AUTOSAR XML (schema 00048)
package /MICROSAR/NvM_swc/DataTypes
  impl type NvM_RequestResultType: compu {0=NVM_REQ_OK, 1=NVM_REQ_NOT_OK, 2=NVM_REQ_PENDING, 3=NVM_REQ_INTEGRITY_FAILED, 4=NVM_REQ_BLOCK_SKIPPED, 5=NVM_REQ_NV_INVALIDATED, 6=NVM_REQ_CANCELED, 7=NVM_REQ_REDUNDANCY_FAILED, 8=NVM_REQ_RESTORED_FROM_ROM}, range raw 0..8, implementation-data-type=uint8
  impl type NvM_BlockIdType: range raw 1..32767, implementation-data-type=uint16
package /MICROSAR/NvM_swc/Interfaces
  client server interface NvMAdministration: is-service=true, service-kind=NON-VOLATILE-RAM-MANAGER
    operation SetBlockProtection: possible-error=NvMAdministration/E_NOT_OK
      arg ProtectionEnabled: type=boolean, direction=IN
    error E_NOT_OK: error-code=1
  client server interface NvMService_AC3_SRBS_Defs: is-service=true, service-kind=NON-VOLATILE-RAM-MANAGER
    7 x operation, all with possible-error=NvMService_AC3_SRBS_Defs/E_NOT_OK:
      GetErrorStatus
        arg ErrorStatus: type=NvM_RequestResultType, direction=OUT
      SetRamBlockStatus
        arg RamBlockStatus: type=boolean, direction=IN
      ReadBlock
        arg DstPtr: type=dtRef_VOID, direction=IN
      WriteBlock
        arg SrcPtr: type=dtRef_const_VOID, direction=IN
      RestoreBlockDefaults
        arg DstPtr: type=dtRef_VOID, direction=IN
      InvalidateNvBlock
      EraseBlock
    error E_NOT_OK: error-code=1
package /MICROSAR/NvM_swc/ComponentTypes
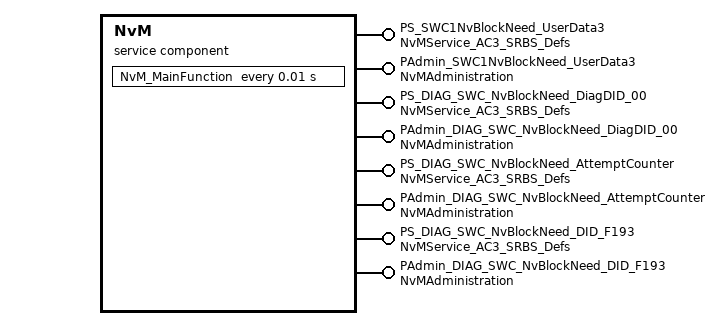
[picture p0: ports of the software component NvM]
  service sw component type NvM: category=SERVICE_COMPONENT
    8 x provide port:
      PS_SWC1NvBlockNeed_UserData3: provided-interface=NvMService_AC3_SRBS_Defs
      PAdmin_SWC1NvBlockNeed_UserData3: provided-interface=NvMAdministration
      PS_DIAG_SWC_NvBlockNeed_DiagDID_00: provided-interface=NvMService_AC3_SRBS_Defs
      PAdmin_DIAG_SWC_NvBlockNeed_DiagDID_00: provided-interface=NvMAdministration
      PS_DIAG_SWC_NvBlockNeed_AttemptCounter: provided-interface=NvMService_AC3_SRBS_Defs
      PAdmin_DIAG_SWC_NvBlockNeed_AttemptCounter: provided-interface=NvMAdministration
      PS_DIAG_SWC_NvBlockNeed_DID_F193: provided-interface=NvMService_AC3_SRBS_Defs
      PAdmin_DIAG_SWC_NvBlockNeed_DID_F193: provided-interface=NvMAdministration
    behavior NvMInternalBehavior: handle-termination-and-restart=NO-SUPPORT
      timing event Timer_NvM_MainFunction: start-on-event=NvM_MainFunction, period=0.01
      32 x operation invoked event:
        OpEventGetErrorStatus_GetErrorStatus_PS_SWC1NvBlockNeed_UserData3: start-on-event=GetErrorStatus, operation=PS_SWC1NvBlockNeed_UserData3.GetErrorStatus
        OpEventSetRamBlockStatus_SetRamBlockStatus_PS_SWC1NvBlockNeed_UserData3: start-on-event=SetRamBlockStatus, operation=PS_SWC1NvBlockNeed_UserData3.SetRamBlockStatus
        OpEventReadBlock_ReadBlock_PS_SWC1NvBlockNeed_UserData3: start-on-event=ReadBlock, operation=PS_SWC1NvBlockNeed_UserData3.ReadBlock
        OpEventWriteBlock_WriteBlock_PS_SWC1NvBlockNeed_UserData3: start-on-event=WriteBlock, operation=PS_SWC1NvBlockNeed_UserData3.WriteBlock
        OpEventRestoreBlockDefaults_RestoreBlockDefaults_PS_SWC1NvBlockNeed_UserData3: start-on-event=RestoreBlockDefaults, operation=PS_SWC1NvBlockNeed_UserData3.RestoreBlockDefaults
        OpEventInvalidateNvBlock_InvalidateNvBlock_PS_SWC1NvBlockNeed_UserData3: start-on-event=InvalidateNvBlock, operation=PS_SWC1NvBlockNeed_UserData3.InvalidateNvBlock
        OpEventEraseBlock_EraseBlock_PS_SWC1NvBlockNeed_UserData3: start-on-event=EraseBlock, operation=PS_SWC1NvBlockNeed_UserData3.EraseBlock
        OpEventSetBlockProtection_SetBlockProtection_PAdmin_SWC1NvBlockNeed_UserData3: start-on-event=SetBlockProtection, operation=PAdmin_SWC1NvBlockNeed_UserData3.SetBlockProtection
        OpEventGetErrorStatus_GetErrorStatus_PS_DIAG_SWC_NvBlockNeed_DiagDID_00: start-on-event=GetErrorStatus, operation=PS_DIAG_SWC_NvBlockNeed_DiagDID_00.GetErrorStatus
        OpEventSetRamBlockStatus_SetRamBlockStatus_PS_DIAG_SWC_NvBlockNeed_DiagDID_00: start-on-event=SetRamBlockStatus, operation=PS_DIAG_SWC_NvBlockNeed_DiagDID_00.SetRamBlockStatus
        OpEventReadBlock_ReadBlock_PS_DIAG_SWC_NvBlockNeed_DiagDID_00: start-on-event=ReadBlock, operation=PS_DIAG_SWC_NvBlockNeed_DiagDID_00.ReadBlock
        OpEventWriteBlock_WriteBlock_PS_DIAG_SWC_NvBlockNeed_DiagDID_00: start-on-event=WriteBlock, operation=PS_DIAG_SWC_NvBlockNeed_DiagDID_00.WriteBlock
        OpEventRestoreBlockDefaults_RestoreBlockDefaults_PS_DIAG_SWC_NvBlockNeed_DiagDID_00: start-on-event=RestoreBlockDefaults, operation=PS_DIAG_SWC_NvBlockNeed_DiagDID_00.RestoreBlockDefaults
        OpEventInvalidateNvBlock_InvalidateNvBlock_PS_DIAG_SWC_NvBlockNeed_DiagDID_00: start-on-event=InvalidateNvBlock, operation=PS_DIAG_SWC_NvBlockNeed_DiagDID_00.InvalidateNvBlock
        OpEventEraseBlock_EraseBlock_PS_DIAG_SWC_NvBlockNeed_DiagDID_00: start-on-event=EraseBlock, operation=PS_DIAG_SWC_NvBlockNeed_DiagDID_00.EraseBlock
        OpEventSetBlockProtection_SetBlockProtection_PAdmin_DIAG_SWC_NvBlockNeed_DiagDID_00: start-on-event=SetBlockProtection, operation=PAdmin_DIAG_SWC_NvBlockNeed_DiagDID_00.SetBlockProtection
        OpEventGetErrorStatus_GetErrorStatus_PS_DIAG_SWC_NvBlockNeed_AttemptCounter: start-on-event=GetErrorStatus, operation=PS_DIAG_SWC_NvBlockNeed_AttemptCounter.GetErrorStatus
        OpEventSetRamBlockStatus_SetRamBlockStatus_PS_DIAG_SWC_NvBlockNeed_AttemptCounter: start-on-event=SetRamBlockStatus, operation=PS_DIAG_SWC_NvBlockNeed_AttemptCounter.SetRamBlockStatus
        OpEventReadBlock_ReadBlock_PS_DIAG_SWC_NvBlockNeed_AttemptCounter: start-on-event=ReadBlock, operation=PS_DIAG_SWC_NvBlockNeed_AttemptCounter.ReadBlock
        OpEventWriteBlock_WriteBlock_PS_DIAG_SWC_NvBlockNeed_AttemptCounter: start-on-event=WriteBlock, operation=PS_DIAG_SWC_NvBlockNeed_AttemptCounter.WriteBlock
        OpEventRestoreBlockDefaults_RestoreBlockDefaults_PS_DIAG_SWC_NvBlockNeed_AttemptCounter: start-on-event=RestoreBlockDefaults, operation=PS_DIAG_SWC_NvBlockNeed_AttemptCounter.RestoreBlockDefaults
        OpEventInvalidateNvBlock_InvalidateNvBlock_PS_DIAG_SWC_NvBlockNeed_AttemptCounter: start-on-event=InvalidateNvBlock, operation=PS_DIAG_SWC_NvBlockNeed_AttemptCounter.InvalidateNvBlock
        OpEventEraseBlock_EraseBlock_PS_DIAG_SWC_NvBlockNeed_AttemptCounter: start-on-event=EraseBlock, operation=PS_DIAG_SWC_NvBlockNeed_AttemptCounter.EraseBlock
        OpEventSetBlockProtection_SetBlockProtection_PAdmin_DIAG_SWC_NvBlockNeed_AttemptCounter: start-on-event=SetBlockProtection, operation=PAdmin_DIAG_SWC_NvBlockNeed_AttemptCounter.SetBlockProtection
        OpEventGetErrorStatus_GetErrorStatus_PS_DIAG_SWC_NvBlockNeed_DID_F193: start-on-event=GetErrorStatus, operation=PS_DIAG_SWC_NvBlockNeed_DID_F193.GetErrorStatus
        OpEventSetRamBlockStatus_SetRamBlockStatus_PS_DIAG_SWC_NvBlockNeed_DID_F193: start-on-event=SetRamBlockStatus, operation=PS_DIAG_SWC_NvBlockNeed_DID_F193.SetRamBlockStatus
        OpEventReadBlock_ReadBlock_PS_DIAG_SWC_NvBlockNeed_DID_F193: start-on-event=ReadBlock, operation=PS_DIAG_SWC_NvBlockNeed_DID_F193.ReadBlock
        OpEventWriteBlock_WriteBlock_PS_DIAG_SWC_NvBlockNeed_DID_F193: start-on-event=WriteBlock, operation=PS_DIAG_SWC_NvBlockNeed_DID_F193.WriteBlock
        OpEventRestoreBlockDefaults_RestoreBlockDefaults_PS_DIAG_SWC_NvBlockNeed_DID_F193: start-on-event=RestoreBlockDefaults, operation=PS_DIAG_SWC_NvBlockNeed_DID_F193.RestoreBlockDefaults
        OpEventInvalidateNvBlock_InvalidateNvBlock_PS_DIAG_SWC_NvBlockNeed_DID_F193: start-on-event=InvalidateNvBlock, operation=PS_DIAG_SWC_NvBlockNeed_DID_F193.InvalidateNvBlock
        OpEventEraseBlock_EraseBlock_PS_DIAG_SWC_NvBlockNeed_DID_F193: start-on-event=EraseBlock, operation=PS_DIAG_SWC_NvBlockNeed_DID_F193.EraseBlock
        OpEventSetBlockProtection_SetBlockProtection_PAdmin_DIAG_SWC_NvBlockNeed_DID_F193: start-on-event=SetBlockProtection, operation=PAdmin_DIAG_SWC_NvBlockNeed_DID_F193.SetBlockProtection
      port-api-options:
        {enable-take-address=true, indirect-api=false, port-defined-argument-value{value=11, value-type=NvM_BlockIdType}, port=PS_SWC1NvBlockNeed_UserData3}
        {enable-take-address=true, indirect-api=false, port-defined-argument-value{value=11, value-type=NvM_BlockIdType}, port=PAdmin_SWC1NvBlockNeed_UserData3}
        {enable-take-address=true, indirect-api=false, port-defined-argument-value{value=12, value-type=NvM_BlockIdType}, port=PS_DIAG_SWC_NvBlockNeed_DiagDID_00}
        {enable-take-address=true, indirect-api=false, port-defined-argument-value{value=12, value-type=NvM_BlockIdType}, port=PAdmin_DIAG_SWC_NvBlockNeed_DiagDID_00}
        {enable-take-address=true, indirect-api=false, port-defined-argument-value{value=13, value-type=NvM_BlockIdType}, port=PS_DIAG_SWC_NvBlockNeed_AttemptCounter}
        {enable-take-address=true, indirect-api=false, port-defined-argument-value{value=13, value-type=NvM_BlockIdType}, port=PAdmin_DIAG_SWC_NvBlockNeed_AttemptCounter}
        {enable-take-address=true, indirect-api=false, port-defined-argument-value{value=14, value-type=NvM_BlockIdType}, port=PS_DIAG_SWC_NvBlockNeed_DID_F193}
        {enable-take-address=true, indirect-api=false, port-defined-argument-value{value=14, value-type=NvM_BlockIdType}, port=PAdmin_DIAG_SWC_NvBlockNeed_DID_F193}
      9 x runnable:
        NvM_MainFunction
        GetErrorStatus: can-be-invoked-concurrently=true, symbol=NvM_GetErrorStatus
        SetRamBlockStatus: can-be-invoked-concurrently=true, symbol=NvM_SetRamBlockStatus
        ReadBlock: can-be-invoked-concurrently=true, symbol=NvM_ReadBlock
        WriteBlock: can-be-invoked-concurrently=true, symbol=NvM_WriteBlock
        RestoreBlockDefaults: can-be-invoked-concurrently=true, symbol=NvM_RestoreBlockDefaults
        InvalidateNvBlock: can-be-invoked-concurrently=true, symbol=NvM_InvalidateNvBlock
        EraseBlock: can-be-invoked-concurrently=true, symbol=NvM_EraseNvBlock
        SetBlockProtection: can-be-invoked-concurrently=true, symbol=NvM_SetBlockProtection
  swc implementation NvMImplementation: programming-language=C, behavior=NvMInternalBehavior
